VERSION ""

NS_ :

BS_:

BU_: ePark_DECU

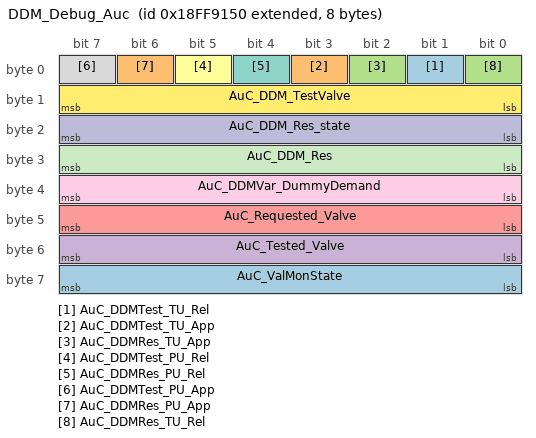
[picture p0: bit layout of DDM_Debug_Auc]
BO_ 2566885712 DDM_Debug_Auc: 8 ePark_DECU
 SG_ AuC_DDMTest_TU_Rel : 1|1@1+ (1,0) [0|1] "" Vector__XXX
 SG_ AuC_DDMTest_TU_App : 3|1@1+ (1,0) [0|1] "" Vector__XXX
 SG_ AuC_DDMRes_TU_App : 2|1@1+ (1,0) [0|1] "" Vector__XXX
 SG_ AuC_Tested_Valve : 48|8@1+ (1,0) [0|4] "" Vector__XXX
 SG_ AuC_Requested_Valve : 40|8@1+ (1,0) [0|4] "" Vector__XXX
 SG_ AuC_DDMTest_PU_Rel : 5|1@1+ (1,0) [0|1] "" Vector__XXX
 SG_ AuC_DDMRes_PU_Rel : 4|1@1+ (1,0) [0|1] "" Vector__XXX
 SG_ AuC_DDMTest_PU_App : 7|1@1+ (1,0) [0|1] "" Vector__XXX
 SG_ AuC_DDMVar_DummyDemand : 32|8@1+ (1,0) [0|8] "" Vector__XXX
 SG_ AuC_DDM_Res_state : 16|8@1+ (1,0) [0|3] "" Vector__XXX
 SG_ AuC_DDM_Res : 24|8@1+ (1,0) [0|3] "" Vector__XXX
 SG_ AuC_DDM_TestValve : 8|8@1+ (1,0) [0|8] "" Vector__XXX
 SG_ AuC_ValMonState : 56|8@1+ (1,0) [0|4] "" Vector__XXX
 SG_ AuC_DDMRes_PU_App : 6|1@1+ (1,0) [0|1] "" Vector__XXX
 SG_ AuC_DDMRes_TU_Rel : 0|1@1+ (1,0) [0|1] "" Vector__XXX

BA_DEF_  "GenEnvVarPrefix" STRING ;
BA_DEF_  "GenEnvVarEndingSnd" STRING ;
BA_DEF_  "GenEnvVarEndingDsp" STRING ;
BA_DEF_ SG_  "SigType" ENUM  "Default","Range","RangeSigned","ASCII","Discrete","Control","ReferencePGN","DTC","StringDelimiter","StringLength","StringLengthControl","MessageCounter","MessageChecksum";
BA_DEF_ SG_  "GenSigEVName" STRING ;
BA_DEF_ SG_  "GenSigILSupport" ENUM  "No","Yes";
BA_DEF_ SG_  "GenSigSendType" ENUM  "Cyclic","OnWrite","OnWriteWithRepetition","OnChange","OnChangeWithRepetition","IfActive","IfActiveWithRepetition","NoSigSendType";
BA_DEF_ BO_  "GenMsgILSupport" ENUM  "No","Yes";
BA_DEF_ BU_  "NmStationAddress" INT 0 255;
BA_DEF_ BO_  "GenMsgSendType" ENUM  "cyclic","NotUsed","IfActive","NotUsed","NotUsed","NotUsed","NotUsed","NotUsed","noMsgSendType";
BA_DEF_ BO_  "GenMsgRequestable" INT 0 1;
BA_DEF_ BO_  "GenMsgCycleTime" INT 0 3600000;
BA_DEF_  "DBName" STRING ;
BA_DEF_  "BusType" STRING ;
BA_DEF_  "ProtocolType" STRING ;
BA_DEF_ BO_  "VFrameFormat" ENUM  "StandardCAN","ExtendedCAN","reserved","J1939PG";
BA_DEF_DEF_  "GenEnvVarPrefix" "Env";
BA_DEF_DEF_  "GenEnvVarEndingSnd" "_";
BA_DEF_DEF_  "GenEnvVarEndingDsp" "Dsp_";
BA_DEF_DEF_  "SigType" "Default";
BA_DEF_DEF_  "GenSigEVName" "Env@Nodename_@Signame";
BA_DEF_DEF_  "GenSigILSupport" "Yes";
BA_DEF_DEF_  "GenSigSendType" "NoSigSendType";
BA_DEF_DEF_  "GenMsgILSupport" "Yes";
BA_DEF_DEF_  "NmStationAddress" 254;
BA_DEF_DEF_  "GenMsgSendType" "noMsgSendType";
BA_DEF_DEF_  "GenMsgRequestable" 1;
BA_DEF_DEF_  "GenMsgCycleTime" 0;
BA_DEF_DEF_  "DBName" "";
BA_DEF_DEF_  "BusType" "CAN";
BA_DEF_DEF_  "ProtocolType" "J1939";
BA_DEF_DEF_  "VFrameFormat" "J1939PG";
BA_ "DBName" "epark_DECU_DDM_AUC";
BA_ "NmStationAddress" BU_ ePark_DECU 80;
BA_ "GenMsgSendType" BO_ 2566885712 0;
BA_ "GenMsgCycleTime" BO_ 2566885712 5;
VAL_ 2566885712 AuC_DDMTest_TU_Rel 1 "True" 0 "False" ;
VAL_ 2566885712 AuC_DDMTest_TU_App 1 "True" 0 "False" ;
VAL_ 2566885712 AuC_DDMRes_TU_App 1 "True" 0 "False" ;
VAL_ 2566885712 AuC_Tested_Valve 3 "TURel" 2 "TUApp" 1 "PURel" 0 "PUApp" ;
VAL_ 2566885712 AuC_Requested_Valve 3 "TURel" 2 "TUApp" 1 "PURel" 0 "PUApp" ;
VAL_ 2566885712 AuC_DDMTest_PU_Rel 1 "True" 0 "False" ;
VAL_ 2566885712 AuC_DDMRes_PU_Rel 1 "True" 0 "False" ;
VAL_ 2566885712 AuC_DDMTest_PU_App 1 "True" 0 "False" ;
VAL_ 2566885712 AuC_DDMVar_DummyDemand 8 "Test_TURel" 7 "Undefined" 6 "Undefined" 5 "Undefined" 4 "Test_TUApp" 3 "Undefined" 2 "Test_PuRel" 1 "Test_PUApp" 0 "TestNoValve" ;
VAL_ 2566885712 AuC_DDM_Res_state 3 "Idle" 2 "Working" 1 "Pass" 0 "Fail" ;
VAL_ 2566885712 AuC_DDM_Res 1 "Pass" 0 "Fail" ;
VAL_ 2566885712 AuC_DDM_TestValve 8 "Test_TURel" 7 "Undefined" 6 "Undefined" 5 "Undefined" 4 "Test_TUApp" 3 "Undefined" 2 "Test_PuRel" 1 "Test_PUApp" 0 "TestNoValve" ;
VAL_ 2566885712 AuC_ValMonState 3 "Undefined" 2 "Active" 1 "Passive" 0 "Idle" ;
VAL_ 2566885712 AuC_DDMRes_PU_App 1 "True" 0 "False" ;
VAL_ 2566885712 AuC_DDMRes_TU_Rel 1 "True" 0 "False" ;
